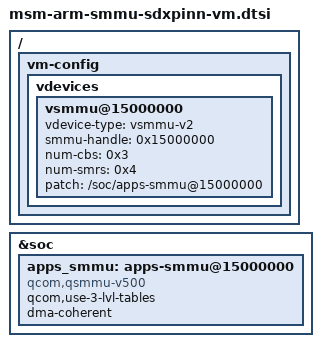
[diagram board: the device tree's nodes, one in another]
#include <dt-bindings/interrupt-controller/arm-gic.h>

/ {
	vm-config {
		vdevices {
			vsmmu@15000000 {
				vdevice-type = "vsmmu-v2";
				smmu-handle = <0x15000000>;
				num-cbs = <0x3>;
				num-smrs = <0x4>;
				patch = "/soc/apps-smmu@15000000";
			};
		};
	};
};

&soc {
	apps_smmu: apps-smmu@15000000 {
		/*
		 * reg, #global-interrupts & interrupts  properties will
		 * be added dynamically by bootloader.
		 */
		compatible = "qcom,qsmmu-v500", "qcom,virt-smmu";
		#iommu-cells = <2>;
		qcom,use-3-lvl-tables;
		dma-coherent;
	};
};
